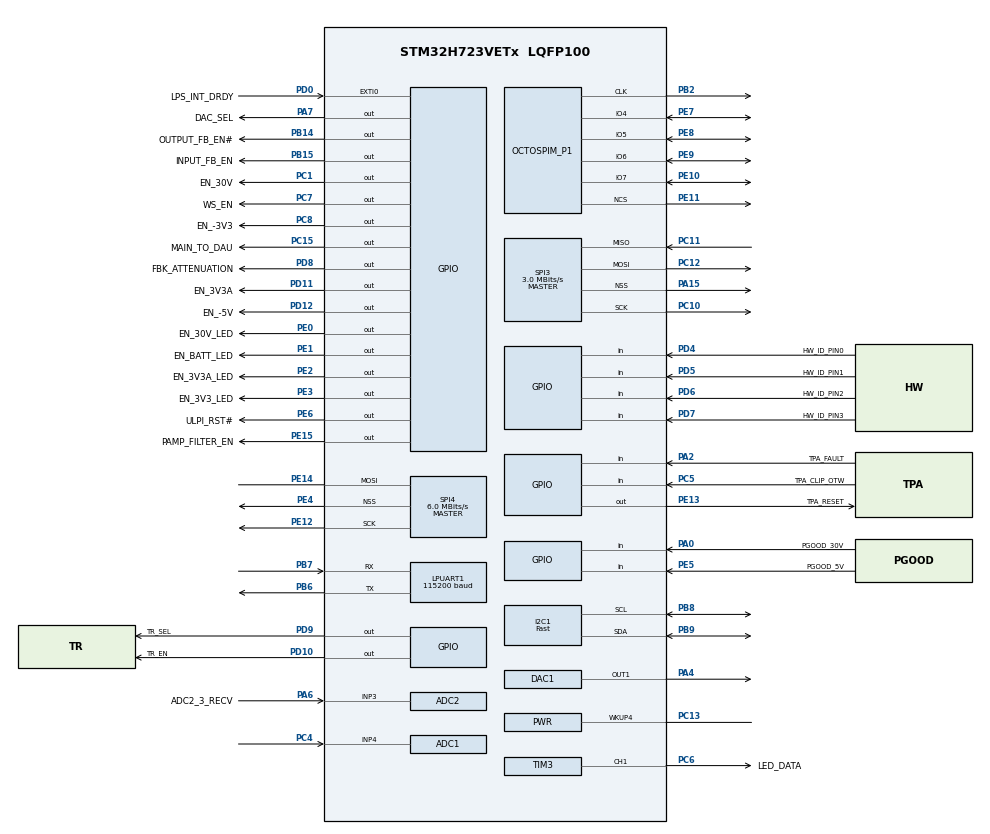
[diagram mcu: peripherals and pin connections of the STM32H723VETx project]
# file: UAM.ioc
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ADC1.Channel-1\#ChannelRegularConversion=ADC_CHANNEL_4
ADC1.ConversionDataManagement=ADC_CONVERSIONDATA_DMA_CIRCULAR
ADC1.ExternalTrigConv=ADC_EXTERNALTRIG_T6_TRGO
ADC1.NbrOfConversionFlag=1
ADC1.OffsetNumber-1\#ChannelRegularConversion=ADC_OFFSET_NONE
ADC1.OffsetSignedSaturation-1\#ChannelRegularConversion=DISABLE
ADC1.Rank-1\#ChannelRegularConversion=1
ADC1.SamplingTime-1\#ChannelRegularConversion=ADC_SAMPLETIME_2CYCLES_5
ADC1.master=1
ADC2.Channel-0\#ChannelRegularConversion=ADC_CHANNEL_3
ADC2.ConversionDataManagement=ADC_CONVERSIONDATA_DMA_CIRCULAR
ADC2.ExternalTrigConv=ADC_EXTERNALTRIG_T8_TRGO
ADC2.NbrOfConversion=1
ADC2.NbrOfConversionFlag=1
ADC2.OffsetNumber-0\#ChannelRegularConversion=ADC_OFFSET_NONE
ADC2.OffsetSignedSaturation-0\#ChannelRegularConversion=DISABLE
ADC2.OversamplingMode=DISABLE
ADC2.Rank-0\#ChannelRegularConversion=1
ADC2.Ratio=1
ADC2.Resolution=ADC_RESOLUTION_16B
ADC2.SamplingTime-0\#ChannelRegularConversion=ADC_SAMPLETIME_2CYCLES_5
ADC3.Channel-0\#ChannelRegularConversion=ADC_CHANNEL_TEMPSENSOR
ADC3.ContinuousConvMode=DISABLE
ADC3.ConversionDataManagement=ADC_CONVERSIONDATA_DR
ADC3.DMAContinuousRequests=DISABLE
ADC3.ExternalTrigConv=ADC_SOFTWARE_START
ADC3.NbrOfConversion=1
ADC3.NbrOfConversionFlag=1
ADC3.OffsetNumber-0\#ChannelRegularConversion=ADC_OFFSET_NONE
ADC3.OffsetSign-0\#ChannelRegularConversion=ADC3_OFFSET_SIGN_NEGATIVE
ADC3.Overrun=ADC_OVR_DATA_PRESERVED
ADC3.OversamplingMode=ENABLE
ADC3.Rank-0\#ChannelRegularConversion=1
ADC3.Ratio=ADC3_OVERSAMPLING_RATIO_16
ADC3.RightBitShift=ADC_RIGHTBITSHIFT_4
ADC3.SamplingTime-0\#ChannelRegularConversion=ADC3_SAMPLETIME_640CYCLES_5
Bdma.LPUART1_RX.0.Direction=DMA_PERIPH_TO_MEMORY
Bdma.LPUART1_RX.0.EventEnable=DISABLE
Bdma.LPUART1_RX.0.Instance=BDMA_Channel0
Bdma.LPUART1_RX.0.MemDataAlignment=DMA_MDATAALIGN_BYTE
Bdma.LPUART1_RX.0.MemInc=DMA_MINC_ENABLE
Bdma.LPUART1_RX.0.Mode=DMA_NORMAL
Bdma.LPUART1_RX.0.PeriphDataAlignment=DMA_PDATAALIGN_BYTE
Bdma.LPUART1_RX.0.PeriphInc=DMA_PINC_DISABLE
Bdma.LPUART1_RX.0.Polarity=HAL_DMAMUX_REQ_GEN_RISING
Bdma.LPUART1_RX.0.Priority=DMA_PRIORITY_MEDIUM
Bdma.LPUART1_RX.0.RequestNumber=1
Bdma.LPUART1_RX.0.SignalID=NONE
Bdma.LPUART1_RX.0.SyncEnable=DISABLE
Bdma.LPUART1_RX.0.SyncPolarity=HAL_DMAMUX_SYNC_NO_EVENT
Bdma.LPUART1_RX.0.SyncRequestNumber=1
Bdma.LPUART1_RX.0.SyncSignalID=NONE
Bdma.LPUART1_TX.1.Direction=DMA_MEMORY_TO_PERIPH
Bdma.LPUART1_TX.1.EventEnable=DISABLE
Bdma.LPUART1_TX.1.Instance=BDMA_Channel1
Bdma.LPUART1_TX.1.MemDataAlignment=DMA_MDATAALIGN_BYTE
Bdma.LPUART1_TX.1.MemInc=DMA_MINC_ENABLE
Bdma.LPUART1_TX.1.Mode=DMA_NORMAL
Bdma.LPUART1_TX.1.PeriphDataAlignment=DMA_PDATAALIGN_BYTE
Bdma.LPUART1_TX.1.PeriphInc=DMA_PINC_DISABLE
Bdma.LPUART1_TX.1.Polarity=HAL_DMAMUX_REQ_GEN_RISING
Bdma.LPUART1_TX.1.Priority=DMA_PRIORITY_MEDIUM
Bdma.LPUART1_TX.1.RequestNumber=1
Bdma.LPUART1_TX.1.SignalID=NONE
Bdma.LPUART1_TX.1.SyncEnable=DISABLE
Bdma.LPUART1_TX.1.SyncPolarity=HAL_DMAMUX_SYNC_NO_EVENT
Bdma.LPUART1_TX.1.SyncRequestNumber=1
Bdma.LPUART1_TX.1.SyncSignalID=NONE
Bdma.Request0=LPUART1_RX
Bdma.Request1=LPUART1_TX
Bdma.RequestsNb=2
CORTEX_M7.AccessPermission_S-Cortex_Memory_Protection_Unit_Region1_Settings_S=MPU_REGION_FULL_ACCESS
CORTEX_M7.AccessPermission_S-Cortex_Memory_Protection_Unit_Region2_Settings_S=MPU_REGION_FULL_ACCESS
CORTEX_M7.AccessPermission_Spec=MPU_REGION_NO_ACCESS
CORTEX_M7.BaseAddress_S-Cortex_Memory_Protection_Unit_Region1_Settings_S=0x30000000
CORTEX_M7.BaseAddress_S-Cortex_Memory_Protection_Unit_Region2_Settings_S=0x38800000
CORTEX_M7.CPU_DCache=Enabled
CORTEX_M7.CPU_ICache=Enabled
CORTEX_M7.DisableExec_S-Cortex_Memory_Protection_Unit_Region1_Settings_S=MPU_INSTRUCTION_ACCESS_DISABLE
CORTEX_M7.DisableExec_S-Cortex_Memory_Protection_Unit_Region2_Settings_S=MPU_INSTRUCTION_ACCESS_DISABLE
CORTEX_M7.DisableExec_Spec=MPU_INSTRUCTION_ACCESS_DISABLE
CORTEX_M7.Enable_S-Cortex_Memory_Protection_Unit_Region1_Settings_S=MPU_REGION_ENABLE
CORTEX_M7.Enable_S-Cortex_Memory_Protection_Unit_Region2_Settings_S=MPU_REGION_ENABLE
CORTEX_M7.IsBufferable_Spec=MPU_ACCESS_NOT_BUFFERABLE
CORTEX_M7.IsCacheable_Spec=MPU_ACCESS_NOT_CACHEABLE
CORTEX_M7.IsShareable_S-Cortex_Memory_Protection_Unit_Region1_Settings_S=MPU_ACCESS_NOT_SHAREABLE
CORTEX_M7.IsShareable_Spec=MPU_ACCESS_NOT_SHAREABLE
CORTEX_M7.Size_S-Cortex_Memory_Protection_Unit_Region1_Settings_S=MPU_REGION_SIZE_32KB
CORTEX_M7.Size_S-Cortex_Memory_Protection_Unit_Region2_Settings_S=MPU_REGION_SIZE_4KB
CORTEX_M7.Size_Spec=MPU_REGION_SIZE_4GB
CORTEX_M7.TypeExtField_S-Cortex_Memory_Protection_Unit_Region1_Settings_S=MPU_TEX_LEVEL0
CORTEX_M7.default_mode_Activation=1
DAC1.DAC_Channel-DAC_OUT1=DAC_CHANNEL_1
DAC1.DAC_Trigger-DAC_OUT1=DAC_TRIGGER_T6_TRGO
Dma.ADC1.2.Direction=DMA_PERIPH_TO_MEMORY
Dma.ADC1.2.EventEnable=DISABLE
Dma.ADC1.2.FIFOMode=DMA_FIFOMODE_DISABLE
Dma.ADC1.2.Instance=DMA2_Stream0
Dma.ADC1.2.MemDataAlignment=DMA_MDATAALIGN_HALFWORD
Dma.ADC1.2.MemInc=DMA_MINC_ENABLE
Dma.ADC1.2.Mode=DMA_CIRCULAR
Dma.ADC1.2.PeriphDataAlignment=DMA_PDATAALIGN_HALFWORD
Dma.ADC1.2.PeriphInc=DMA_PINC_DISABLE
Dma.ADC1.2.Polarity=HAL_DMAMUX_REQ_GEN_RISING
Dma.ADC1.2.Priority=DMA_PRIORITY_VERY_HIGH
Dma.ADC1.2.RequestNumber=1
Dma.ADC1.2.SignalID=NONE
Dma.ADC1.2.SyncEnable=DISABLE
Dma.ADC1.2.SyncPolarity=HAL_DMAMUX_SYNC_NO_EVENT
Dma.ADC1.2.SyncRequestNumber=1
Dma.ADC1.2.SyncSignalID=NONE
Dma.ADC2.1.Direction=DMA_PERIPH_TO_MEMORY
Dma.ADC2.1.EventEnable=DISABLE
Dma.ADC2.1.FIFOMode=DMA_FIFOMODE_DISABLE
Dma.ADC2.1.Instance=DMA2_Stream2
Dma.ADC2.1.MemDataAlignment=DMA_MDATAALIGN_HALFWORD
Dma.ADC2.1.MemInc=DMA_MINC_ENABLE
Dma.ADC2.1.Mode=DMA_CIRCULAR
Dma.ADC2.1.PeriphDataAlignment=DMA_PDATAALIGN_HALFWORD
Dma.ADC2.1.PeriphInc=DMA_PINC_DISABLE
Dma.ADC2.1.Polarity=HAL_DMAMUX_REQ_GEN_RISING
Dma.ADC2.1.Priority=DMA_PRIORITY_VERY_HIGH
Dma.ADC2.1.RequestNumber=1
Dma.ADC2.1.SignalID=NONE
Dma.ADC2.1.SyncEnable=DISABLE
Dma.ADC2.1.SyncPolarity=HAL_DMAMUX_SYNC_NO_EVENT
Dma.ADC2.1.SyncRequestNumber=1
Dma.ADC2.1.SyncSignalID=NONE
Dma.DAC1_CH1.3.Direction=DMA_MEMORY_TO_PERIPH
Dma.DAC1_CH1.3.EventEnable=DISABLE
Dma.DAC1_CH1.3.FIFOMode=DMA_FIFOMODE_DISABLE
Dma.DAC1_CH1.3.Instance=DMA1_Stream1
Dma.DAC1_CH1.3.MemDataAlignment=DMA_MDATAALIGN_HALFWORD
Dma.DAC1_CH1.3.MemInc=DMA_MINC_ENABLE
Dma.DAC1_CH1.3.Mode=DMA_CIRCULAR
Dma.DAC1_CH1.3.PeriphDataAlignment=DMA_PDATAALIGN_HALFWORD
Dma.DAC1_CH1.3.PeriphInc=DMA_PINC_DISABLE
Dma.DAC1_CH1.3.Polarity=HAL_DMAMUX_REQ_GEN_RISING
Dma.DAC1_CH1.3.Priority=DMA_PRIORITY_VERY_HIGH
Dma.DAC1_CH1.3.RequestNumber=1
Dma.DAC1_CH1.3.SignalID=NONE
Dma.DAC1_CH1.3.SyncEnable=DISABLE
Dma.DAC1_CH1.3.SyncPolarity=HAL_DMAMUX_SYNC_NO_EVENT
Dma.DAC1_CH1.3.SyncRequestNumber=1
Dma.DAC1_CH1.3.SyncSignalID=NONE
Dma.Request0=TIM3_CH1
Dma.Request1=ADC2
Dma.Request2=ADC1
Dma.Request3=DAC1_CH1
Dma.Request4=SPI4_RX
Dma.Request5=SPI4_TX
Dma.SPI4_RX.4.Direction=DMA_PERIPH_TO_MEMORY
Dma.SPI4_RX.4.EventEnable=DISABLE
Dma.SPI4_RX.4.FIFOMode=DMA_FIFOMODE_DISABLE
Dma.SPI4_RX.4.Instance=DMA1_Stream4
Dma.SPI4_RX.4.MemDataAlignment=DMA_MDATAALIGN_HALFWORD
Dma.SPI4_RX.4.MemInc=DMA_MINC_ENABLE
Dma.SPI4_RX.4.Mode=DMA_NORMAL
Dma.SPI4_RX.4.PeriphDataAlignment=DMA_PDATAALIGN_HALFWORD
Dma.SPI4_RX.4.PeriphInc=DMA_PINC_DISABLE
Dma.SPI4_RX.4.Polarity=HAL_DMAMUX_REQ_GEN_RISING
Dma.SPI4_RX.4.Priority=DMA_PRIORITY_MEDIUM
Dma.SPI4_RX.4.RequestNumber=1
Dma.SPI4_RX.4.SignalID=NONE
Dma.SPI4_RX.4.SyncEnable=DISABLE
Dma.SPI4_RX.4.SyncPolarity=HAL_DMAMUX_SYNC_NO_EVENT
Dma.SPI4_RX.4.SyncRequestNumber=1
Dma.SPI4_RX.4.SyncSignalID=NONE
Dma.SPI4_TX.5.Direction=DMA_MEMORY_TO_PERIPH
Dma.SPI4_TX.5.EventEnable=DISABLE
Dma.SPI4_TX.5.FIFOMode=DMA_FIFOMODE_DISABLE
Dma.SPI4_TX.5.Instance=DMA1_Stream3
Dma.SPI4_TX.5.MemDataAlignment=DMA_MDATAALIGN_HALFWORD
Dma.SPI4_TX.5.MemInc=DMA_MINC_ENABLE
Dma.SPI4_TX.5.Mode=DMA_NORMAL
Dma.SPI4_TX.5.PeriphDataAlignment=DMA_PDATAALIGN_HALFWORD
Dma.SPI4_TX.5.PeriphInc=DMA_PINC_DISABLE
Dma.SPI4_TX.5.Polarity=HAL_DMAMUX_REQ_GEN_RISING
Dma.SPI4_TX.5.Priority=DMA_PRIORITY_MEDIUM
Dma.SPI4_TX.5.RequestNumber=1
Dma.SPI4_TX.5.SignalID=NONE
Dma.SPI4_TX.5.SyncEnable=DISABLE
Dma.SPI4_TX.5.SyncPolarity=HAL_DMAMUX_SYNC_NO_EVENT
Dma.SPI4_TX.5.SyncRequestNumber=1
Dma.SPI4_TX.5.SyncSignalID=NONE
Dma.TIM3_CH1.0.Direction=DMA_MEMORY_TO_PERIPH
Dma.TIM3_CH1.0.EventEnable=DISABLE
Dma.TIM3_CH1.0.FIFOMode=DMA_FIFOMODE_DISABLE
Dma.TIM3_CH1.0.Instance=DMA1_Stream0
Dma.TIM3_CH1.0.MemDataAlignment=DMA_MDATAALIGN_HALFWORD
Dma.TIM3_CH1.0.MemInc=DMA_MINC_ENABLE
Dma.TIM3_CH1.0.Mode=DMA_NORMAL
Dma.TIM3_CH1.0.PeriphDataAlignment=DMA_PDATAALIGN_HALFWORD
Dma.TIM3_CH1.0.PeriphInc=DMA_PINC_DISABLE
Dma.TIM3_CH1.0.Polarity=HAL_DMAMUX_REQ_GEN_RISING
Dma.TIM3_CH1.0.Priority=DMA_PRIORITY_HIGH
Dma.TIM3_CH1.0.RequestNumber=1
Dma.TIM3_CH1.0.SignalID=NONE
Dma.TIM3_CH1.0.SyncEnable=DISABLE
Dma.TIM3_CH1.0.SyncPolarity=HAL_DMAMUX_SYNC_NO_EVENT
Dma.TIM3_CH1.0.SyncRequestNumber=1
Dma.TIM3_CH1.0.SyncSignalID=NONE
FREERTOS.HEAP_NUMBER=4
FREERTOS.Mutexes01=dau_uart_mutex,Dynamic,NULL,Available
FREERTOS.Tasks01=tusb_task,47,2048,startTusbTask,Default,NULL,Static,tusb_task_buffer,tusb_task_control_block;message_task,44,8192,startMessTask,Default,NULL,Static,mess_task_buffer,mess_task_control_block;sys_task,31,256,startSystemManagementTask,Default,NULL,Static,sys_task_buffer,sys_task_control_block;comm_task,30,2048,startCommunicationTask,Default,NULL,Static,comm_task_buffer,comm_task_control_block;cfg_task,16,512,startconfigTask,Default,NULL,Static,cfg_task_buffer,cfg_task_control_block;dac_task,46,1024,startDacTask,Default,NULL,Static,dac_task_buffer,dac_task_control_block;mac_task,25,2048,startMacTask,Default,NULL,Static,mac_task_buffer,mac_task_control_block;filt_task,45,512,startFiltTask,Default,NULL,Static,filt_task_buffer,filt_task_control_block;hil_task,46,1024,startHilTask,Default,NULL,Static,hil_task_buffer,hil_task_control_block
FREERTOS.configCHECK_FOR_STACK_OVERFLOW=2
FREERTOS.configENABLE_FPU=1
FREERTOS.configGENERATE_RUN_TIME_STATS=1
FREERTOS.configRECORD_STACK_HIGH_ADDRESS=0
FREERTOS.configTOTAL_HEAP_SIZE=48000
FREERTOS.configUSE_NEWLIB_REENTRANT=1
FREERTOS.configUSE_TICKLESS_IDLE=1
I2C1.I2C_Speed_Mode=I2C_Fast
I2C1.Timing=0x00B03FDB
LPUART1.BaudRate=115200
Mcu.Family=STM32H7
Mcu.Name=STM32H723VETx
Mcu.Package=LQFP100
NVIC.ADC3_IRQn=true\:5\:0\:false\:false\:true\:true\:true\:true\:true
NVIC.BDMA_Channel0_IRQn=true\:5\:0\:false\:false\:true\:true\:false\:true\:true
NVIC.BDMA_Channel1_IRQn=true\:5\:0\:false\:false\:true\:true\:false\:true\:true
NVIC.DMA1_Stream0_IRQn=true\:5\:0\:false\:false\:true\:true\:false\:true\:true
NVIC.DMA1_Stream1_IRQn=true\:5\:0\:false\:false\:true\:true\:false\:true\:true
NVIC.DMA1_Stream3_IRQn=true\:5\:0\:false\:false\:true\:false\:false\:true\:true
NVIC.DMA1_Stream4_IRQn=true\:5\:0\:false\:false\:true\:true\:false\:true\:true
NVIC.DMA2_Stream0_IRQn=true\:5\:0\:false\:false\:true\:false\:false\:true\:true
NVIC.DMA2_Stream2_IRQn=true\:5\:0\:false\:false\:true\:true\:false\:true\:true
NVIC.EXTI0_IRQn=true\:5\:0\:false\:false\:true\:true\:true\:true\:true
NVIC.FMAC_IRQn=true\:5\:0\:false\:false\:true\:true\:true\:true\:true
NVIC.I2C1_EV_IRQn=true\:5\:0\:false\:false\:true\:true\:true\:true\:true
NVIC.LPUART1_IRQn=true\:5\:0\:false\:false\:true\:true\:true\:true\:true
NVIC.PriorityGroup=NVIC_PRIORITYGROUP_4
NVIC.SPI3_IRQn=true\:5\:0\:false\:false\:true\:true\:true\:true\:true
NVIC.SPI4_IRQn=true\:5\:0\:false\:false\:true\:true\:true\:true\:true
NVIC.TIM16_IRQn=true\:5\:0\:false\:false\:true\:true\:true\:true\:true
NVIC.TIM17_IRQn=true\:5\:0\:false\:false\:true\:true\:true\:true\:true
NVIC.TIM2_IRQn=true\:15\:0\:false\:false\:true\:false\:false\:true\:true
NVIC.TIM3_IRQn=true\:5\:0\:false\:false\:true\:true\:true\:true\:true
NVIC.TIM6_DAC_IRQn=true\:5\:0\:false\:false\:true\:true\:true\:true\:true
NVIC.TimeBase=TIM2_IRQn
NVIC.TimeBaseIP=TIM2
OCTOSPI1.ClockPrescaler=2
PA0.GPIO_Label=PGOOD_30V
PA0.Signal=GPIO_Input
PA13(JTMS/SWDIO).Mode=Trace_Asynchronous_SW
PA13(JTMS/SWDIO).Signal=DEBUG_JTMS-SWDIO
PA14(JTCK/SWCLK).Mode=Trace_Asynchronous_SW
PA14(JTCK/SWCLK).Signal=DEBUG_JTCK-SWCLK
PA15(JTDI).Mode=NSS_Signal_Hard_Output
PA15(JTDI).Signal=SPI3_NSS
PA2.GPIO_Label=TPA_FAULT
PA2.Signal=GPIO_Input
PA4.Signal=COMP_DAC11_group
PA6.GPIO_Label=ADC2_3_RECV
PA6.Signal=ADCx_INP3
PA7.GPIO_Label=DAC_SEL
PA7.Signal=GPIO_Output
PB14.GPIO_Label=OUTPUT_FB_EN\#
PB14.Signal=GPIO_Output
PB15.GPIO_Label=INPUT_FB_EN
PB15.Signal=GPIO_Output
PB2.Mode=O1_P1_CLK
PB2.Signal=OCTOSPIM_P1_CLK
PB3(JTDO/TRACESWO).Mode=Trace_Asynchronous_SW
PB3(JTDO/TRACESWO).Signal=DEBUG_JTDO-SWO
PB6.Mode=Asynchronous
PB6.Signal=LPUART1_TX
PB7.Mode=Asynchronous
PB7.Signal=LPUART1_RX
PB8.Mode=I2C
PB8.Signal=I2C1_SCL
PB9.Mode=I2C
PB9.Signal=I2C1_SDA
PC1.GPIO_Label=EN_30V
PC1.Signal=GPIO_Output
PC10.Mode=Full_Duplex_Master
PC10.Signal=SPI3_SCK
PC11.Mode=Full_Duplex_Master
PC11.Signal=SPI3_MISO
PC12.Mode=Full_Duplex_Master
PC12.Signal=SPI3_MOSI
PC13.Mode=WakeUp4
PC13.Signal=PWR_WKUP4
PC14-OSC32_IN.Mode=LSE-External-Clock-Source
PC14-OSC32_IN.Signal=RCC_OSC32_IN
PC15-OSC32_OUT.GPIO_Label=MAIN_TO_DAU
PC15-OSC32_OUT.Signal=GPIO_Output
PC4.Signal=ADCx_INP4
PC5.GPIO_Label=TPA_CLIP_OTW
PC5.Signal=GPIO_Input
PC6.GPIO_Label=LED_DATA
PC6.Signal=S_TIM3_CH1
PC7.GPIO_Label=WS_EN
PC7.Signal=GPIO_Output
PC8.GPIO_Label=EN_-3V3
PC8.Signal=GPIO_Output
PD0.GPIO_Label=LPS_INT_DRDY
PD0.GPIO_PuPd=GPIO_PULLDOWN
PD0.Signal=GPXTI0
PD10.GPIO_Label=TR_EN
PD10.Signal=GPIO_Output
PD11.GPIO_Label=EN_3V3A
PD11.Signal=GPIO_Output
PD12.GPIO_Label=EN_-5V
PD12.Signal=GPIO_Output
PD4.GPIO_Label=HW_ID_PIN0
PD4.Signal=GPIO_Input
PD5.GPIO_Label=HW_ID_PIN1
PD5.Signal=GPIO_Input
PD6.GPIO_Label=HW_ID_PIN2
PD6.Signal=GPIO_Input
PD7.GPIO_Label=HW_ID_PIN3
PD7.Signal=GPIO_Input
PD8.GPIO_Label=FBK_ATTENUATION
PD8.PinState=GPIO_PIN_SET
PD8.Signal=GPIO_Output
PD9.GPIO_Label=TR_SEL
PD9.Signal=GPIO_Output
PE0.GPIO_Label=EN_30V_LED
PE0.Signal=GPIO_Output
PE1.GPIO_Label=EN_BATT_LED
PE1.Signal=GPIO_Output
PE10.Mode=OCTOSPI1_IOL_Port1H
PE10.Signal=OCTOSPIM_P1_IO7
PE11.Mode=OCTOSPI1_Port1_NCS
PE11.Signal=OCTOSPIM_P1_NCS
PE12.Mode=Simplex_Bidirectional_Master
PE12.Signal=SPI4_SCK
PE13.GPIO_Label=TPA_RESET
PE13.Signal=GPIO_Output
PE14.Mode=Simplex_Bidirectional_Master
PE14.Signal=SPI4_MOSI
PE15.GPIO_Label=PAMP_FILTER_EN
PE15.Signal=GPIO_Output
PE2.GPIO_Label=EN_3V3A_LED
PE2.Signal=GPIO_Output
PE3.GPIO_Label=EN_3V3_LED
PE3.Signal=GPIO_Output
PE4.Mode=NSS_Signal_Hard_Output
PE4.Signal=SPI4_NSS
PE5.GPIO_Label=PGOOD_5V
PE5.Signal=GPIO_Input
PE6.GPIO_Label=ULPI_RST\#
PE6.Signal=GPIO_Output
PE7.Mode=OCTOSPI1_IOL_Port1H
PE7.Signal=OCTOSPIM_P1_IO4
PE8.Mode=OCTOSPI1_IOL_Port1H
PE8.Signal=OCTOSPIM_P1_IO5
PE9.Mode=OCTOSPI1_IOL_Port1H
PE9.Signal=OCTOSPIM_P1_IO6
PH0-OSC_IN.Mode=HSE-External-Oscillator
PH0-OSC_IN.Signal=RCC_OSC_IN
PH1-OSC_OUT.Mode=HSE-External-Oscillator
PH1-OSC_OUT.Signal=RCC_OSC_OUT
ProjectManager.HeapSize=0x200
ProjectManager.StackSize=0x400
ProjectManager.TargetToolchain=STM32CubeIDE
RCC.ADCFreq_Value=48000000
RCC.APB1Freq_Value=120000000
RCC.APB2Freq_Value=120000000
RCC.APB3Freq_Value=120000000
RCC.APB4Freq_Value=120000000
RCC.CortexFreq_Value=480000000
RCC.D1PPRE=RCC_APB3_DIV2
RCC.D2PPRE1=RCC_APB1_DIV2
RCC.D2PPRE2=RCC_APB2_DIV2
RCC.D3PPRE=RCC_APB4_DIV2
RCC.DIVM1=1
RCC.DIVM2=1
RCC.DIVM3=4
RCC.DIVN1=60
RCC.DIVN2=24
RCC.DIVN3=120
RCC.DIVP1=1
RCC.DIVP2=4
RCC.DIVQ1=10
RCC.DIVQ3=5
RCC.HCLKFreq_Value=240000000
RCC.HPRE=RCC_HCLK_DIV2
RCC.HSE_VALUE=8000000
RCC.PLL1_VCO_SEL-AdvancedSettings=RCC_PLL1VCOMEDIUM
RCC.PLL2FRACN=0
RCC.PLL2_VCI_Range-AdvancedSettings=RCC_PLL2VCIRANGE_0
RCC.PLL3FRACN=0
RCC.PLLFRACN=0
RCC.PLLSourceVirtual=RCC_PLLSOURCE_HSE
RCC.PWR_Regulator_Voltage_Scale=PWR_REGULATOR_VOLTAGE_SCALE0
RCC.RTCClockSelection=RCC_RTCCLKSOURCE_LSE
RCC.SYSCLKFreq_VALUE=480000000
RCC.SYSCLKSource=RCC_SYSCLKSOURCE_PLLCLK
RCC.Spi45ClockSelection=RCC_SPI45CLKSOURCE_PLL2
RCC.USBCLockSelection=RCC_USBCLKSOURCE_PLL3
RCC.USBFreq_Value=48000000
SH.ADCx_INP3.0=ADC2_INP3,IN3-Single-Ended
SH.ADCx_INP4.0=ADC1_INP4,IN4-Single-Ended
SH.COMP_DAC11_group.0=DAC1_OUT1,DAC_OUT1
SH.S_TIM3_CH1.0=TIM3_CH1,PWM Generation1 CH1
SPI3.BaudRatePrescaler=SPI_BAUDRATEPRESCALER_16
SPI3.CalculateBaudRate=3.0 MBits/s
SPI3.DataSize=SPI_DATASIZE_8BIT
SPI3.Direction=SPI_DIRECTION_2LINES
SPI3.Mode=SPI_MODE_MASTER
SPI3.VirtualNSS=VM_NSSHARD
SPI3.VirtualType=VM_MASTER
SPI4.BaudRatePrescaler=SPI_BAUDRATEPRESCALER_16
SPI4.CalculateBaudRate=6.0 MBits/s
SPI4.DataSize=SPI_DATASIZE_16BIT
SPI4.Direction=SPI_DIRECTION_1LINE
SPI4.Mode=SPI_MODE_MASTER
SPI4.VirtualNSS=VM_NSSHARD
SPI4.VirtualType=VM_MASTER
TIM16.Period=1000-1
TIM16.Prescaler=240-1
TIM17.Period=100-1
TIM17.Prescaler=240-1
TIM3.Channel-PWM\ Generation1\ CH1=TIM_CHANNEL_1
TIM3.OCFastMode_PWM-PWM\ Generation1\ CH1=TIM_OCFAST_DISABLE
TIM3.OCPolarity_1=TIM_OCPOLARITY_LOW
TIM3.Period=100-1
TIM3.Prescaler=3-1
TIM3.Pulse-PWM\ Generation1\ CH1=0
TIM6.Period=4-1
TIM6.Prescaler=120-1
TIM6.TIM_MasterOutputTrigger=TIM_TRGO_UPDATE
TIM8.AutoReloadPreload=TIM_AUTORELOAD_PRELOAD_ENABLE
TIM8.CounterMode=TIM_COUNTERMODE_UP
TIM8.Period=2-1
TIM8.Prescaler=1000-1
TIM8.TIM_MasterOutputTrigger=TIM_TRGO_UPDATE
VP_ADC3_TempSens_Input.Mode=IN-TempSens
VP_CORDIC_VS_CORDIC.Mode=CORDIC_Activate
VP_DTS_VS-DTS.Mode=DTS
VP_FMAC_VS_FMAC.Mode=FMAC_Activate
VP_FREERTOS_VS_CMSIS_V2.Mode=CMSIS_V2
VP_MEMORYMAP_VS_MEMORYMAP.Mode=CurAppReg
VP_OCTOSPI1_VS_quad.Mode=quad_mode
VP_RTC_VS_RTC_Activate.Mode=RTC_Enabled
VP_SYS_VS_tim2.Mode=TIM2
VP_TIM16_VS_ClockSourceINT.Mode=Enable_Timer
VP_TIM17_VS_ClockSourceINT.Mode=Enable_Timer
VP_TIM3_VS_ClockSourceINT.Mode=Internal
VP_TIM6_VS_ClockSourceINT.Mode=Enable_Timer
VP_TIM8_VS_ClockSourceINT.Mode=Internal
VP_VREFBUF_V_VREFBUF.Mode=ExternalMode
board=custom

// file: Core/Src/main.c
/* USER CODE BEGIN Header */
/**
  ******************************************************************************
  * @file           : main.c
  * @brief          : Main program body
  ******************************************************************************
  * @attention
  *
  * Copyright (c) 2025 STMicroelectronics.
  * All rights reserved.
  *
  * This software is licensed under terms that can be found in the LICENSE file
  * in the root directory of this software component.
  * If no LICENSE file comes with this software, it is provided AS-IS.
  *
  ******************************************************************************
  */

  /**
  * Modifications Copyright (c) 2025 OpenAquatix Contributors
  * Licensed under MIT License (see LICENSE file)
  *
  * Modified by: Addition of OpenAquatix application
  */

/* USER CODE END Header */
#include "main.h"
#include "FreeRTOS.h"
#include "cmsis_os2.h"

/* USER CODE BEGIN Includes */
#include "ws2812b-driver.h"
#include "pga113-driver.h"
#include "power_leds.h"
#include "hmi_usb.h"
#include "comm_main.h"
#include "mess_main.h"
#include "cfg_main.h"
#include "sys_main.h"
#include "dac_main.h"
#include "mac_main.h"
#include "filt_main.h"
#include "cfg_parameters.h"
#include "stm32h7xx_ll_cordic.h"
#include "pwr_domains.h"
#include "core_cm7.h"
#include "tusb.h"
#include "usb_main.h"
#include "hil_main.h"
/* USER CODE END Includes */

typedef StaticTask_t osStaticThreadDef_t;

ADC_HandleTypeDef hadc1;
ADC_HandleTypeDef hadc2;
ADC_HandleTypeDef hadc3;
DMA_HandleTypeDef hdma_adc1;
DMA_HandleTypeDef hdma_adc2;

CORDIC_HandleTypeDef hcordic;

DAC_HandleTypeDef hdac1;
DMA_HandleTypeDef hdma_dac1_ch1;

DTS_HandleTypeDef hdts;

FMAC_HandleTypeDef hfmac;

I2C_HandleTypeDef hi2c1;

UART_HandleTypeDef hlpuart1;
DMA_HandleTypeDef hdma_lpuart1_rx;
DMA_HandleTypeDef hdma_lpuart1_tx;

OSPI_HandleTypeDef hospi1;

RTC_HandleTypeDef hrtc;

SPI_HandleTypeDef hspi3;
SPI_HandleTypeDef hspi4;
DMA_HandleTypeDef hdma_spi4_rx;
DMA_HandleTypeDef hdma_spi4_tx;

TIM_HandleTypeDef htim3;
TIM_HandleTypeDef htim6;
TIM_HandleTypeDef htim8;
TIM_HandleTypeDef htim16;
TIM_HandleTypeDef htim17;
DMA_HandleTypeDef hdma_tim3_ch1;

/* Definitions for tusb_task */
osThreadId_t tusb_taskHandle;
uint32_t tusb_task_buffer[ 2048 ];
osStaticThreadDef_t tusb_task_control_block;
const osThreadAttr_t tusb_task_attributes = {
  .name = "USB",
  .cb_mem = &tusb_task_control_block,
  .cb_size = sizeof(tusb_task_control_block),
  .stack_mem = &tusb_task_buffer[0],
  .stack_size = sizeof(tusb_task_buffer),
  .priority = (osPriority_t) osPriorityHigh7,
};
/* Definitions for message_task */
osThreadId_t message_taskHandle;
uint32_t mess_task_buffer[ 8192 ] __attribute__((section(".dtcm")));
osStaticThreadDef_t mess_task_control_block;
const osThreadAttr_t message_task_attributes = {
  .name = MESS_TASK_NAME,
  .cb_mem = &mess_task_control_block,
  .cb_size = sizeof(mess_task_control_block),
  .stack_mem = &mess_task_buffer[0],
  .stack_size = sizeof(mess_task_buffer),
  .priority = (osPriority_t) osPriorityHigh4,
};
/* Definitions for sys_task */
osThreadId_t sys_taskHandle;
uint32_t sys_task_buffer[ 256 ];
osStaticThreadDef_t sys_task_control_block;
const osThreadAttr_t sys_task_attributes = {
  .name = "SYS",
  .cb_mem = &sys_task_control_block,
  .cb_size = sizeof(sys_task_control_block),
  .stack_mem = &sys_task_buffer[0],
  .stack_size = sizeof(sys_task_buffer),
  .priority = (osPriority_t) osPriorityNormal7,
};
/* Definitions for comm_task */
osThreadId_t comm_taskHandle;
uint32_t comm_task_buffer[ 2048 ];
osStaticThreadDef_t comm_task_control_block;
const osThreadAttr_t comm_task_attributes = {
  .name = "COMM",
  .cb_mem = &comm_task_control_block,
  .cb_size = sizeof(comm_task_control_block),
  .stack_mem = &comm_task_buffer[0],
  .stack_size = sizeof(comm_task_buffer),
  .priority = (osPriority_t) osPriorityNormal6,
};
/* Definitions for cfg_task */
osThreadId_t cfg_taskHandle;
uint32_t cfg_task_buffer[ 512 ];
osStaticThreadDef_t cfg_task_control_block;
const osThreadAttr_t cfg_task_attributes = {
  .name = "CFG",
  .cb_mem = &cfg_task_control_block,
  .cb_size = sizeof(cfg_task_control_block),
  .stack_mem = &cfg_task_buffer[0],
  .stack_size = sizeof(cfg_task_buffer),
  .priority = (osPriority_t) osPriorityBelowNormal,
};
/* Definitions for dac_task */
osThreadId_t dac_taskHandle;
uint32_t dac_task_buffer[ 1024 ];
osStaticThreadDef_t dac_task_control_block;
const osThreadAttr_t dac_task_attributes = {
  .name = "DAC",
  .cb_mem = &dac_task_control_block,
  .cb_size = sizeof(dac_task_control_block),
  .stack_mem = &dac_task_buffer[0],
  .stack_size = sizeof(dac_task_buffer),
  .priority = (osPriority_t) osPriorityHigh6,
};
/* Definitions for mac_task */
osThreadId_t mac_taskHandle;
uint32_t mac_task_buffer[ 2048 ];
osStaticThreadDef_t mac_task_control_block;
const osThreadAttr_t mac_task_attributes = {
  .name = "MAC",
  .cb_mem = &mac_task_control_block,
  .cb_size = sizeof(mac_task_control_block),
  .stack_mem = &mac_task_buffer[0],
  .stack_size = sizeof(mac_task_buffer),
  .priority = (osPriority_t) osPriorityNormal1,
};
/* Definitions for filt_task */
osThreadId_t filt_taskHandle;
uint32_t filt_task_buffer[ 512 ];
osStaticThreadDef_t filt_task_control_block;
const osThreadAttr_t filt_task_attributes = {
  .name = FILT_TASK_NAME,
  .cb_mem = &filt_task_control_block,
  .cb_size = sizeof(filt_task_control_block),
  .stack_mem = &filt_task_buffer[0],
  .stack_size = sizeof(filt_task_buffer),
  .priority = (osPriority_t) osPriorityHigh5,
};
/* Definitions for hil_task */
osThreadId_t hil_taskHandle;
uint32_t hil_task_buffer[ 1024 ];
osStaticThreadDef_t hil_task_control_block;
const osThreadAttr_t hil_task_attributes = {
  .name = "HIL",
  .cb_mem = &hil_task_control_block,
  .cb_size = sizeof(hil_task_control_block),
  .stack_mem = &hil_task_buffer[0],
  .stack_size = sizeof(hil_task_buffer),
  .priority = (osPriority_t) osPriorityHigh6,
};
/* Definitions for dau_uart_mutex */
osMutexId_t dau_uart_mutexHandle;
const osMutexAttr_t dau_uart_mutex_attributes = {
  .name = "dau_uart_mutex"
};
/* USER CODE BEGIN PV */
osEventFlagsId_t print_event_handle = NULL;
/* USER CODE END PV */

void SystemClock_Config(void);
void PeriphCommonClock_Config(void);
static void MPU_Config(void);
static void MX_GPIO_Init(void);
static void MX_DMA_Init(void);
static void MX_BDMA_Init(void);
static void MX_ADC1_Init(void);
static void MX_ADC3_Init(void);
static void MX_DAC1_Init(void);
static void MX_DTS_Init(void);
static void MX_I2C1_Init(void);
static void MX_SPI4_Init(void);
static void MX_TIM3_Init(void);
static void MX_TIM6_Init(void);
static void MX_TIM8_Init(void);
static void MX_ADC2_Init(void);
static void MX_TIM17_Init(void);
static void MX_TIM16_Init(void);
static void MX_CORDIC_Init(void);
static void MX_LPUART1_UART_Init(void);
static void MX_OCTOSPI1_Init(void);
static void MX_RTC_Init(void);
static void MX_SPI3_Init(void);
static void MX_FMAC_Init(void);
void startTusbTask(void *argument);
void startMessTask(void *argument);
void startSystemManagementTask(void *argument);
void startCommunicationTask(void *argument);
void startconfigTask(void *argument);
void startDacTask(void *argument);
void startMacTask(void *argument);
void startFiltTask(void *argument);
void startHilTask(void *argument);

/* USER CODE BEGIN PFP */
static void usbHsInit(void);
/* USER CODE END PFP */

/* USER CODE BEGIN 0 */
extern __IO uint32_t uwTick;
extern HAL_TickFreqTypeDef uwTickFreq;
static uint32_t tick_rollover_count = 0;
void HAL_IncTick(void)
{
  if (uwTick == 0xFFFFFFFF) tick_rollover_count++;
  uwTick += (uint32_t)uwTickFreq;
}

uint32_t HAL_TickRolloverCount(void)
{
  return tick_rollover_count;
}

uint64_t HAL_AbsoluteTimestamp(void)
{
  return uwTick | (((uint64_t) HAL_TickRolloverCount()) << 32);
}

static void usbHsInit(void)
{
  GPIO_InitTypeDef GPIO_InitStruct = {0};
  RCC_PeriphCLKInitTypeDef PeriphClkInitStruct = {0};

  PeriphClkInitStruct.PeriphClockSelection = RCC_PERIPHCLK_USB;
  PeriphClkInitStruct.PLL3.PLL3M = 4;
  PeriphClkInitStruct.PLL3.PLL3N = 120;
  PeriphClkInitStruct.PLL3.PLL3P = 2;
  PeriphClkInitStruct.PLL3.PLL3Q = 5;
  PeriphClkInitStruct.PLL3.PLL3R = 2;
  PeriphClkInitStruct.PLL3.PLL3RGE = RCC_PLL3VCIRANGE_1;
  PeriphClkInitStruct.PLL3.PLL3VCOSEL = RCC_PLL3VCOWIDE;
  PeriphClkInitStruct.PLL3.PLL3FRACN = 0;
  PeriphClkInitStruct.UsbClockSelection = RCC_USBCLKSOURCE_PLL3;
  if (HAL_RCCEx_PeriphCLKConfig(&PeriphClkInitStruct) != HAL_OK)
  {
    Error_Handler();
  }

/** Enable USB Voltage detector
*/
  HAL_PWREx_EnableUSBVoltageDetector();

  __HAL_RCC_GPIOC_CLK_ENABLE();
  __HAL_RCC_GPIOA_CLK_ENABLE();
  __HAL_RCC_GPIOB_CLK_ENABLE();
  /**USB_OTG_HS GPIO Configuration
  PC0     ------> USB_OTG_HS_ULPI_STP
  PC2_C     ------> USB_OTG_HS_ULPI_DIR
  PC3_C     ------> USB_OTG_HS_ULPI_NXT
  PA3     ------> USB_OTG_HS_ULPI_D0
  PA5     ------> USB_OTG_HS_ULPI_CK
  PB0     ------> USB_OTG_HS_ULPI_D1
  PB1     ------> USB_OTG_HS_ULPI_D2
  PB10     ------> USB_OTG_HS_ULPI_D3
  PB11     ------> USB_OTG_HS_ULPI_D4
  PB12     ------> USB_OTG_HS_ULPI_D5
  PB13     ------> USB_OTG_HS_ULPI_D6
  PB5     ------> USB_OTG_HS_ULPI_D7
  */
  GPIO_InitStruct.Pin = GPIO_PIN_0|GPIO_PIN_2|GPIO_PIN_3;
  GPIO_InitStruct.Mode = GPIO_MODE_AF_PP;
  GPIO_InitStruct.Pull = GPIO_NOPULL;
  GPIO_InitStruct.Speed = GPIO_SPEED_FREQ_HIGH;
  GPIO_InitStruct.Alternate = GPIO_AF10_OTG1_HS;
  HAL_GPIO_Init(GPIOC, &GPIO_InitStruct);

  GPIO_InitStruct.Pin = GPIO_PIN_3|GPIO_PIN_5;
  GPIO_InitStruct.Mode = GPIO_MODE_AF_PP;
  GPIO_InitStruct.Pull = GPIO_NOPULL;
  GPIO_InitStruct.Speed = GPIO_SPEED_FREQ_HIGH;
  GPIO_InitStruct.Alternate = GPIO_AF10_OTG1_HS;
  HAL_GPIO_Init(GPIOA, &GPIO_InitStruct);

  GPIO_InitStruct.Pin = GPIO_PIN_0|GPIO_PIN_1|GPIO_PIN_10|GPIO_PIN_11
                        |GPIO_PIN_12|GPIO_PIN_13|GPIO_PIN_5;
  GPIO_InitStruct.Mode = GPIO_MODE_AF_PP;
  GPIO_InitStruct.Pull = GPIO_NOPULL;
  GPIO_InitStruct.Speed = GPIO_SPEED_FREQ_HIGH;
  GPIO_InitStruct.Alternate = GPIO_AF10_OTG1_HS;
  HAL_GPIO_Init(GPIOB, &GPIO_InitStruct);

  /* Peripheral clock enable */
  __HAL_RCC_USB_OTG_HS_CLK_ENABLE();
  __HAL_RCC_USB_OTG_HS_ULPI_CLK_ENABLE();
  /* USB_OTG_HS interrupt Init */
  HAL_NVIC_SetPriority(OTG_HS_EP1_OUT_IRQn, 5, 0);
  HAL_NVIC_EnableIRQ(OTG_HS_EP1_OUT_IRQn);
  HAL_NVIC_SetPriority(OTG_HS_EP1_IN_IRQn, 5, 0);
  HAL_NVIC_EnableIRQ(OTG_HS_EP1_IN_IRQn);
  HAL_NVIC_SetPriority(OTG_HS_IRQn, 5, 0);
  HAL_NVIC_EnableIRQ(OTG_HS_IRQn);
}

/* USER CODE END 0 */

int main(void)
{

  /* MPU Configuration--------------------------------------------------------*/
  MPU_Config();

  /* Enable the CPU Cache */

  /* Enable I-Cache---------------------------------------------------------*/
  SCB_EnableICache();

  /* Enable D-Cache---------------------------------------------------------*/
  SCB_EnableDCache();

  /* MCU Configuration--------------------------------------------------------*/

  /* Reset of all peripherals, Initializes the Flash interface and the Systick. */
  HAL_Init();

  /* Configure the system clock */
  SystemClock_Config();

  /* Configure the peripherals common clocks */
  PeriphCommonClock_Config();

  /* USER CODE BEGIN SysInit */
  CoreDebug->DEMCR |= CoreDebug_DEMCR_TRCENA_Msk; /* Enable trace */
  DWT->CYCCNT = 0;                                /* Reset counter */
  DWT->CTRL |= DWT_CTRL_CYCCNTENA_Msk;            /* Enable CYCCNT */
  /* USER CODE END SysInit */

  /* Initialize all configured peripherals */
  MX_GPIO_Init();
  MX_DMA_Init();
  MX_BDMA_Init();
  MX_ADC1_Init();
  MX_ADC3_Init();
  MX_DAC1_Init();
  MX_DTS_Init();
  MX_I2C1_Init();
  MX_SPI4_Init();
  MX_TIM3_Init();
  MX_TIM6_Init();
  MX_TIM8_Init();
  MX_ADC2_Init();
  MX_TIM17_Init();
  MX_TIM16_Init();
  MX_CORDIC_Init();
  MX_LPUART1_UART_Init();
  MX_OCTOSPI1_Init();
  MX_RTC_Init();
  MX_SPI3_Init();
  MX_FMAC_Init();
  /* USER CODE BEGIN 2 */
  usbHsInit();
  PWRLED_Update(0x0F);
  PWR_Analog(true);
  HAL_Delay(20);
  Ws2812b_Init();

  if (CFG_CreateFlags() == false) {
    Error_Handler();
  }

  if (Param_Init() == false) {
    Error_Handler();
  }

  /* USER CODE END 2 */

  /* Init scheduler */
  osKernelInitialize();
  /* Create the mutex(es) */
  /* creation of dau_uart_mutex */
  dau_uart_mutexHandle = osMutexNew(&dau_uart_mutex_attributes);

  /* USER CODE BEGIN RTOS_QUEUES */
  /* add queues, ... */
  MESS_InitializeQueues();
  /* USER CODE END RTOS_QUEUES */

  /* Create the thread(s) */
  /* creation of tusb_task */
  tusb_taskHandle = osThreadNew(startTusbTask, NULL, &tusb_task_attributes);

  /* creation of message_task */
  message_taskHandle = osThreadNew(startMessTask, NULL, &message_task_attributes);

  /* creation of sys_task */
  sys_taskHandle = osThreadNew(startSystemManagementTask, NULL, &sys_task_attributes);

  /* creation of comm_task */
  comm_taskHandle = osThreadNew(startCommunicationTask, NULL, &comm_task_attributes);

  /* creation of cfg_task */
  cfg_taskHandle = osThreadNew(startconfigTask, NULL, &cfg_task_attributes);

  /* creation of dac_task */
  dac_taskHandle = osThreadNew(startDacTask, NULL, &dac_task_attributes);

  /* creation of mac_task */
  mac_taskHandle = osThreadNew(startMacTask, NULL, &mac_task_attributes);

  /* creation of filt_task */
  filt_taskHandle = osThreadNew(startFiltTask, NULL, &filt_task_attributes);

  /* creation of hil_task */
  hil_taskHandle = osThreadNew(startHilTask, NULL, &hil_task_attributes);

  /* USER CODE BEGIN RTOS_EVENTS */
  /* add events, ... */
  print_event_handle = osEventFlagsNew(NULL);
  /* USER CODE END RTOS_EVENTS */

  /* Start scheduler */
  osKernelStart();

  /* We should never get here as control is now taken by the scheduler */

  /* Infinite loop */
  while (1)
  {

  }
}

void SystemClock_Config(void)
{
  RCC_OscInitTypeDef RCC_OscInitStruct = {0};
  RCC_ClkInitTypeDef RCC_ClkInitStruct = {0};

  /** Supply configuration update enable
  */
  HAL_PWREx_ConfigSupply(PWR_LDO_SUPPLY);

  /** Configure the main internal regulator output voltage
  */
  __HAL_PWR_VOLTAGESCALING_CONFIG(PWR_REGULATOR_VOLTAGE_SCALE0);

  while(!__HAL_PWR_GET_FLAG(PWR_FLAG_VOSRDY)) {}

  /** Initializes the RCC Oscillators according to the specified parameters
  * in the RCC_OscInitTypeDef structure.
  */
  RCC_OscInitStruct.OscillatorType = RCC_OSCILLATORTYPE_HSE|RCC_OSCILLATORTYPE_LSE;
  RCC_OscInitStruct.HSEState = RCC_HSE_ON;
  RCC_OscInitStruct.LSEState = RCC_LSE_BYPASS;
  RCC_OscInitStruct.PLL.PLLState = RCC_PLL_ON;
  RCC_OscInitStruct.PLL.PLLSource = RCC_PLLSOURCE_HSE;
  RCC_OscInitStruct.PLL.PLLM = 1;
  RCC_OscInitStruct.PLL.PLLN = 60;
  RCC_OscInitStruct.PLL.PLLP = 1;
  RCC_OscInitStruct.PLL.PLLQ = 10;
  RCC_OscInitStruct.PLL.PLLR = 2;
  RCC_OscInitStruct.PLL.PLLRGE = RCC_PLL1VCIRANGE_3;
  RCC_OscInitStruct.PLL.PLLVCOSEL = RCC_PLL1VCOWIDE;
  RCC_OscInitStruct.PLL.PLLFRACN = 0;
  if (HAL_RCC_OscConfig(&RCC_OscInitStruct) != HAL_OK)
  {
    Error_Handler();
  }

  /** Initializes the CPU, AHB and APB buses clocks
  */
  RCC_ClkInitStruct.ClockType = RCC_CLOCKTYPE_HCLK|RCC_CLOCKTYPE_SYSCLK
                              |RCC_CLOCKTYPE_PCLK1|RCC_CLOCKTYPE_PCLK2
                              |RCC_CLOCKTYPE_D3PCLK1|RCC_CLOCKTYPE_D1PCLK1;
  RCC_ClkInitStruct.SYSCLKSource = RCC_SYSCLKSOURCE_PLLCLK;
  RCC_ClkInitStruct.SYSCLKDivider = RCC_SYSCLK_DIV1;
  RCC_ClkInitStruct.AHBCLKDivider = RCC_HCLK_DIV2;
  RCC_ClkInitStruct.APB3CLKDivider = RCC_APB3_DIV2;
  RCC_ClkInitStruct.APB1CLKDivider = RCC_APB1_DIV2;
  RCC_ClkInitStruct.APB2CLKDivider = RCC_APB2_DIV2;
  RCC_ClkInitStruct.APB4CLKDivider = RCC_APB4_DIV2;

  if (HAL_RCC_ClockConfig(&RCC_ClkInitStruct, FLASH_LATENCY_3) != HAL_OK)
  {
    Error_Handler();
  }
}

void PeriphCommonClock_Config(void)
{
  RCC_PeriphCLKInitTypeDef PeriphClkInitStruct = {0};

  /** Initializes the peripherals clock
  */
  PeriphClkInitStruct.PeriphClockSelection = RCC_PERIPHCLK_ADC|RCC_PERIPHCLK_SPI4;
  PeriphClkInitStruct.PLL2.PLL2M = 1;
  PeriphClkInitStruct.PLL2.PLL2N = 24;
  PeriphClkInitStruct.PLL2.PLL2P = 4;
  PeriphClkInitStruct.PLL2.PLL2Q = 2;
  PeriphClkInitStruct.PLL2.PLL2R = 2;
  PeriphClkInitStruct.PLL2.PLL2RGE = RCC_PLL2VCIRANGE_3;
  PeriphClkInitStruct.PLL2.PLL2VCOSEL = RCC_PLL2VCOWIDE;
  PeriphClkInitStruct.PLL2.PLL2FRACN = 0;
  PeriphClkInitStruct.Spi45ClockSelection = RCC_SPI45CLKSOURCE_PLL2;
  PeriphClkInitStruct.AdcClockSelection = RCC_ADCCLKSOURCE_PLL2;
  if (HAL_RCCEx_PeriphCLKConfig(&PeriphClkInitStruct) != HAL_OK)
  {
    Error_Handler();
  }
}

static void MX_ADC1_Init(void)
{

  ADC_MultiModeTypeDef multimode = {0};
  ADC_ChannelConfTypeDef sConfig = {0};

  /** Common config
  */
  hadc1.Instance = ADC1;
  hadc1.Init.ClockPrescaler = ADC_CLOCK_ASYNC_DIV1;
  hadc1.Init.Resolution = ADC_RESOLUTION_16B;
  hadc1.Init.ScanConvMode = ADC_SCAN_DISABLE;
  hadc1.Init.EOCSelection = ADC_EOC_SINGLE_CONV;
  hadc1.Init.LowPowerAutoWait = DISABLE;
  hadc1.Init.ContinuousConvMode = DISABLE;
  hadc1.Init.NbrOfConversion = 1;
  hadc1.Init.DiscontinuousConvMode = DISABLE;
  hadc1.Init.ExternalTrigConv = ADC_EXTERNALTRIG_T6_TRGO;
  hadc1.Init.ExternalTrigConvEdge = ADC_EXTERNALTRIGCONVEDGE_RISING;
  hadc1.Init.ConversionDataManagement = ADC_CONVERSIONDATA_DMA_CIRCULAR;
  hadc1.Init.Overrun = ADC_OVR_DATA_PRESERVED;
  hadc1.Init.LeftBitShift = ADC_LEFTBITSHIFT_NONE;
  hadc1.Init.OversamplingMode = DISABLE;
  hadc1.Init.Oversampling.Ratio = 1;
  if (HAL_ADC_Init(&hadc1) != HAL_OK)
  {
    Error_Handler();
  }

  /** Configure the ADC multi-mode
  */
  multimode.Mode = ADC_MODE_INDEPENDENT;
  if (HAL_ADCEx_MultiModeConfigChannel(&hadc1, &multimode) != HAL_OK)
  {
    Error_Handler();
  }

  /** Configure Regular Channel
  */
  sConfig.Channel = ADC_CHANNEL_4;
  sConfig.Rank = ADC_REGULAR_RANK_1;
  sConfig.SamplingTime = ADC_SAMPLETIME_2CYCLES_5;
  sConfig.SingleDiff = ADC_SINGLE_ENDED;
  sConfig.OffsetNumber = ADC_OFFSET_NONE;
  sConfig.Offset = 0;
  sConfig.OffsetSignedSaturation = DISABLE;
  if (HAL_ADC_ConfigChannel(&hadc1, &sConfig) != HAL_OK)
  {
    Error_Handler();
  }
  /* USER CODE BEGIN ADC1_Init 2 */
  HAL_Delay(1);
  if (HAL_ADCEx_Calibration_Start(&hadc1, ADC_CALIB_OFFSET, ADC_SINGLE_ENDED) != HAL_OK)
  {
    Error_Handler();
  }
  /* USER CODE END ADC1_Init 2 */

}

static void MX_ADC2_Init(void)
{

  ADC_ChannelConfTypeDef sConfig = {0};

  /** Common config
  */
  hadc2.Instance = ADC2;
  hadc2.Init.ClockPrescaler = ADC_CLOCK_ASYNC_DIV1;
  hadc2.Init.Resolution = ADC_RESOLUTION_16B;
  hadc2.Init.ScanConvMode = ADC_SCAN_DISABLE;
  hadc2.Init.EOCSelection = ADC_EOC_SINGLE_CONV;
  hadc2.Init.LowPowerAutoWait = DISABLE;
  hadc2.Init.ContinuousConvMode = DISABLE;
  hadc2.Init.NbrOfConversion = 1;
  hadc2.Init.DiscontinuousConvMode = DISABLE;
  hadc2.Init.ExternalTrigConv = ADC_EXTERNALTRIG_T8_TRGO;
  hadc2.Init.ExternalTrigConvEdge = ADC_EXTERNALTRIGCONVEDGE_RISING;
  hadc2.Init.ConversionDataManagement = ADC_CONVERSIONDATA_DMA_CIRCULAR;
  hadc2.Init.Overrun = ADC_OVR_DATA_PRESERVED;
  hadc2.Init.LeftBitShift = ADC_LEFTBITSHIFT_NONE;
  hadc2.Init.OversamplingMode = DISABLE;
  hadc2.Init.Oversampling.Ratio = 1;
  if (HAL_ADC_Init(&hadc2) != HAL_OK)
  {
    Error_Handler();
  }

  /** Configure Regular Channel
  */
  sConfig.Channel = ADC_CHANNEL_3;
  sConfig.Rank = ADC_REGULAR_RANK_1;
  sConfig.SamplingTime = ADC_SAMPLETIME_2CYCLES_5;
  sConfig.SingleDiff = ADC_SINGLE_ENDED;
  sConfig.OffsetNumber = ADC_OFFSET_NONE;
  sConfig.Offset = 0;
  sConfig.OffsetSignedSaturation = DISABLE;
  if (HAL_ADC_ConfigChannel(&hadc2, &sConfig) != HAL_OK)
  {
    Error_Handler();
  }
  /* USER CODE BEGIN ADC2_Init 2 */
  HAL_Delay(1);
  if (HAL_ADCEx_Calibration_Start(&hadc2, ADC_CALIB_OFFSET, ADC_SINGLE_ENDED) != HAL_OK)
  {
    Error_Handler();
  }
  /* USER CODE END ADC2_Init 2 */

}

static void MX_ADC3_Init(void)
{

  ADC_ChannelConfTypeDef sConfig = {0};

  /** Common config
  */
  hadc3.Instance = ADC3;
  hadc3.Init.ClockPrescaler = ADC_CLOCK_ASYNC_DIV1;
  hadc3.Init.Resolution = ADC_RESOLUTION_12B;
  hadc3.Init.DataAlign = ADC3_DATAALIGN_RIGHT;
  hadc3.Init.ScanConvMode = ADC_SCAN_DISABLE;
  hadc3.Init.EOCSelection = ADC_EOC_SINGLE_CONV;
  hadc3.Init.LowPowerAutoWait = DISABLE;
  hadc3.Init.ContinuousConvMode = DISABLE;
  hadc3.Init.NbrOfConversion = 1;
  hadc3.Init.DiscontinuousConvMode = DISABLE;
  hadc3.Init.ExternalTrigConv = ADC_SOFTWARE_START;
  hadc3.Init.ExternalTrigConvEdge = ADC_EXTERNALTRIGCONVEDGE_NONE;
  hadc3.Init.DMAContinuousRequests = DISABLE;
  hadc3.Init.SamplingMode = ADC_SAMPLING_MODE_NORMAL;
  hadc3.Init.ConversionDataManagement = ADC_CONVERSIONDATA_DR;
  hadc3.Init.Overrun = ADC_OVR_DATA_PRESERVED;
  hadc3.Init.LeftBitShift = ADC_LEFTBITSHIFT_NONE;
  hadc3.Init.OversamplingMode = ENABLE;
  hadc3.Init.Oversampling.Ratio = ADC3_OVERSAMPLING_RATIO_16;
  hadc3.Init.Oversampling.RightBitShift = ADC_RIGHTBITSHIFT_4;
  hadc3.Init.Oversampling.TriggeredMode = ADC_TRIGGEREDMODE_SINGLE_TRIGGER;
  hadc3.Init.Oversampling.OversamplingStopReset = ADC_REGOVERSAMPLING_CONTINUED_MODE;
  if (HAL_ADC_Init(&hadc3) != HAL_OK)
  {
    Error_Handler();
  }

  /** Configure Regular Channel
  */
  sConfig.Channel = ADC_CHANNEL_TEMPSENSOR;
  sConfig.Rank = ADC_REGULAR_RANK_1;
  sConfig.SamplingTime = ADC3_SAMPLETIME_640CYCLES_5;
  sConfig.SingleDiff = ADC_SINGLE_ENDED;
  sConfig.OffsetNumber = ADC_OFFSET_NONE;
  sConfig.Offset = 0;
  sConfig.OffsetSign = ADC3_OFFSET_SIGN_NEGATIVE;
  if (HAL_ADC_ConfigChannel(&hadc3, &sConfig) != HAL_OK)
  {
    Error_Handler();
  }
  /* USER CODE BEGIN ADC3_Init 2 */
  HAL_Delay(1);
  if (HAL_ADCEx_Calibration_Start(&hadc3, ADC_CALIB_OFFSET, ADC_SINGLE_ENDED) != HAL_OK)
  {
    Error_Handler();
  }
  /* USER CODE END ADC3_Init 2 */

}

static void MX_CORDIC_Init(void)
{

  hcordic.Instance = CORDIC;
  if (HAL_CORDIC_Init(&hcordic) != HAL_OK)
  {
    Error_Handler();
  }
  /* USER CODE BEGIN CORDIC_Init 2 */
  LL_CORDIC_Config(CORDIC,
                   LL_CORDIC_FUNCTION_SINE,
                   LL_CORDIC_PRECISION_5CYCLES,
                   LL_CORDIC_SCALE_0,
                   LL_CORDIC_NBWRITE_1,
                   LL_CORDIC_NBREAD_1,
                   LL_CORDIC_INSIZE_32BITS,
                   LL_CORDIC_OUTSIZE_32BITS);
  /* USER CODE END CORDIC_Init 2 */

}

static void MX_DAC1_Init(void)
{

  DAC_ChannelConfTypeDef sConfig = {0};

  /** DAC Initialization
  */
  hdac1.Instance = DAC1;
  if (HAL_DAC_Init(&hdac1) != HAL_OK)
  {
    Error_Handler();
  }

  /** DAC channel OUT1 config
  */
  sConfig.DAC_SampleAndHold = DAC_SAMPLEANDHOLD_DISABLE;
  sConfig.DAC_Trigger = DAC_TRIGGER_T6_TRGO;
  sConfig.DAC_OutputBuffer = DAC_OUTPUTBUFFER_ENABLE;
  sConfig.DAC_ConnectOnChipPeripheral = DAC_CHIPCONNECT_DISABLE;
  sConfig.DAC_UserTrimming = DAC_TRIMMING_FACTORY;
  if (HAL_DAC_ConfigChannel(&hdac1, &sConfig, DAC_CHANNEL_1) != HAL_OK)
  {
    Error_Handler();
  }
  /* USER CODE BEGIN DAC1_Init 2 */
  HAL_DACEx_SelfCalibrate(&hdac1, &sConfig, DAC_CHANNEL_1);
  HAL_Delay(1);
  /* USER CODE END DAC1_Init 2 */

}

static void MX_DTS_Init(void)
{

  hdts.Instance = DTS;
  hdts.Init.QuickMeasure = DTS_QUICKMEAS_DISABLE;
  hdts.Init.RefClock = DTS_REFCLKSEL_PCLK;
  hdts.Init.TriggerInput = DTS_TRIGGER_HW_NONE;
  hdts.Init.SamplingTime = DTS_SMP_TIME_1_CYCLE;
  hdts.Init.Divider = 1;
  hdts.Init.HighThreshold = 0x0;
  hdts.Init.LowThreshold = 0x0;
  if (HAL_DTS_Init(&hdts) != HAL_OK)
  {
    Error_Handler();
  }

}

static void MX_FMAC_Init(void)
{

  hfmac.Instance = FMAC;
  if (HAL_FMAC_Init(&hfmac) != HAL_OK)
  {
    Error_Handler();
  }

}

static void MX_I2C1_Init(void)
{

  hi2c1.Instance = I2C1;
  hi2c1.Init.Timing = 0x00B03FDB;
  hi2c1.Init.OwnAddress1 = 0;
  hi2c1.Init.AddressingMode = I2C_ADDRESSINGMODE_7BIT;
  hi2c1.Init.DualAddressMode = I2C_DUALADDRESS_DISABLE;
  hi2c1.Init.OwnAddress2 = 0;
  hi2c1.Init.OwnAddress2Masks = I2C_OA2_NOMASK;
  hi2c1.Init.GeneralCallMode = I2C_GENERALCALL_DISABLE;
  hi2c1.Init.NoStretchMode = I2C_NOSTRETCH_DISABLE;
  if (HAL_I2C_Init(&hi2c1) != HAL_OK)
  {
    Error_Handler();
  }

  /** Configure Analogue filter
  */
  if (HAL_I2CEx_ConfigAnalogFilter(&hi2c1, I2C_ANALOGFILTER_ENABLE) != HAL_OK)
  {
    Error_Handler();
  }

  /** Configure Digital filter
  */
  if (HAL_I2CEx_ConfigDigitalFilter(&hi2c1, 0) != HAL_OK)
  {
    Error_Handler();
  }

}

static void MX_LPUART1_UART_Init(void)
{

  hlpuart1.Instance = LPUART1;
  hlpuart1.Init.BaudRate = 115200;
  hlpuart1.Init.WordLength = UART_WORDLENGTH_8B;
  hlpuart1.Init.StopBits = UART_STOPBITS_1;
  hlpuart1.Init.Parity = UART_PARITY_NONE;
  hlpuart1.Init.Mode = UART_MODE_TX_RX;
  hlpuart1.Init.HwFlowCtl = UART_HWCONTROL_NONE;
  hlpuart1.Init.OneBitSampling = UART_ONE_BIT_SAMPLE_DISABLE;
  hlpuart1.Init.ClockPrescaler = UART_PRESCALER_DIV1;
  hlpuart1.AdvancedInit.AdvFeatureInit = UART_ADVFEATURE_NO_INIT;
  hlpuart1.FifoMode = UART_FIFOMODE_DISABLE;
  if (HAL_UART_Init(&hlpuart1) != HAL_OK)
  {
    Error_Handler();
  }
  if (HAL_UARTEx_SetTxFifoThreshold(&hlpuart1, UART_TXFIFO_THRESHOLD_1_8) != HAL_OK)
  {
    Error_Handler();
  }
  if (HAL_UARTEx_SetRxFifoThreshold(&hlpuart1, UART_RXFIFO_THRESHOLD_1_8) != HAL_OK)
  {
    Error_Handler();
  }
  if (HAL_UARTEx_DisableFifoMode(&hlpuart1) != HAL_OK)
  {
    Error_Handler();
  }

}

static void MX_OCTOSPI1_Init(void)
{

  OSPIM_CfgTypeDef sOspiManagerCfg = {0};

  /* OCTOSPI1 parameter configuration*/
  hospi1.Instance = OCTOSPI1;
  hospi1.Init.FifoThreshold = 1;
  hospi1.Init.DualQuad = HAL_OSPI_DUALQUAD_DISABLE;
  hospi1.Init.MemoryType = HAL_OSPI_MEMTYPE_MICRON;
  hospi1.Init.DeviceSize = 32;
  hospi1.Init.ChipSelectHighTime = 1;
  hospi1.Init.FreeRunningClock = HAL_OSPI_FREERUNCLK_DISABLE;
  hospi1.Init.ClockMode = HAL_OSPI_CLOCK_MODE_0;
  hospi1.Init.WrapSize = HAL_OSPI_WRAP_NOT_SUPPORTED;
  hospi1.Init.ClockPrescaler = 2;
  hospi1.Init.SampleShifting = HAL_OSPI_SAMPLE_SHIFTING_NONE;
  hospi1.Init.DelayHoldQuarterCycle = HAL_OSPI_DHQC_DISABLE;
  hospi1.Init.ChipSelectBoundary = 0;
  hospi1.Init.DelayBlockBypass = HAL_OSPI_DELAY_BLOCK_BYPASSED;
  hospi1.Init.MaxTran = 0;
  hospi1.Init.Refresh = 0;
  if (HAL_OSPI_Init(&hospi1) != HAL_OK)
  {
    Error_Handler();
  }
  sOspiManagerCfg.ClkPort = 1;
  sOspiManagerCfg.NCSPort = 1;
  sOspiManagerCfg.IOLowPort = HAL_OSPIM_IOPORT_1_HIGH;
  if (HAL_OSPIM_Config(&hospi1, &sOspiManagerCfg, HAL_OSPI_TIMEOUT_DEFAULT_VALUE) != HAL_OK)
  {
    Error_Handler();
  }

}

static void MX_RTC_Init(void)
{

  /** Initialize RTC Only
  */
  hrtc.Instance = RTC;
  hrtc.Init.HourFormat = RTC_HOURFORMAT_24;
  hrtc.Init.AsynchPrediv = 127;
  hrtc.Init.SynchPrediv = 255;
  hrtc.Init.OutPut = RTC_OUTPUT_DISABLE;
  hrtc.Init.OutPutPolarity = RTC_OUTPUT_POLARITY_HIGH;
  hrtc.Init.OutPutType = RTC_OUTPUT_TYPE_OPENDRAIN;
  hrtc.Init.OutPutRemap = RTC_OUTPUT_REMAP_NONE;
  if (HAL_RTC_Init(&hrtc) != HAL_OK)
  {
    Error_Handler();
  }

}

static void MX_SPI3_Init(void)
{

  /* SPI3 parameter configuration*/
  hspi3.Instance = SPI3;
  hspi3.Init.Mode = SPI_MODE_MASTER;
  hspi3.Init.Direction = SPI_DIRECTION_2LINES;
  hspi3.Init.DataSize = SPI_DATASIZE_8BIT;
  hspi3.Init.CLKPolarity = SPI_POLARITY_LOW;
  hspi3.Init.CLKPhase = SPI_PHASE_1EDGE;
  hspi3.Init.NSS = SPI_NSS_HARD_OUTPUT;
  hspi3.Init.BaudRatePrescaler = SPI_BAUDRATEPRESCALER_16;
  hspi3.Init.FirstBit = SPI_FIRSTBIT_MSB;
  hspi3.Init.TIMode = SPI_TIMODE_DISABLE;
  hspi3.Init.CRCCalculation = SPI_CRCCALCULATION_DISABLE;
  hspi3.Init.CRCPolynomial = 0x0;
  hspi3.Init.NSSPMode = SPI_NSS_PULSE_ENABLE;
  hspi3.Init.NSSPolarity = SPI_NSS_POLARITY_LOW;
  hspi3.Init.FifoThreshold = SPI_FIFO_THRESHOLD_01DATA;
  hspi3.Init.TxCRCInitializationPattern = SPI_CRC_INITIALIZATION_ALL_ZERO_PATTERN;
  hspi3.Init.RxCRCInitializationPattern = SPI_CRC_INITIALIZATION_ALL_ZERO_PATTERN;
  hspi3.Init.MasterSSIdleness = SPI_MASTER_SS_IDLENESS_00CYCLE;
  hspi3.Init.MasterInterDataIdleness = SPI_MASTER_INTERDATA_IDLENESS_00CYCLE;
  hspi3.Init.MasterReceiverAutoSusp = SPI_MASTER_RX_AUTOSUSP_DISABLE;
  hspi3.Init.MasterKeepIOState = SPI_MASTER_KEEP_IO_STATE_DISABLE;
  hspi3.Init.IOSwap = SPI_IO_SWAP_DISABLE;
  if (HAL_SPI_Init(&hspi3) != HAL_OK)
  {
    Error_Handler();
  }

}

static void MX_SPI4_Init(void)
{

  /* SPI4 parameter configuration*/
  hspi4.Instance = SPI4;
  hspi4.Init.Mode = SPI_MODE_MASTER;
  hspi4.Init.Direction = SPI_DIRECTION_1LINE;
  hspi4.Init.DataSize = SPI_DATASIZE_16BIT;
  hspi4.Init.CLKPolarity = SPI_POLARITY_LOW;
  hspi4.Init.CLKPhase = SPI_PHASE_1EDGE;
  hspi4.Init.NSS = SPI_NSS_HARD_OUTPUT;
  hspi4.Init.BaudRatePrescaler = SPI_BAUDRATEPRESCALER_16;
  hspi4.Init.FirstBit = SPI_FIRSTBIT_MSB;
  hspi4.Init.TIMode = SPI_TIMODE_DISABLE;
  hspi4.Init.CRCCalculation = SPI_CRCCALCULATION_DISABLE;
  hspi4.Init.CRCPolynomial = 0x0;
  hspi4.Init.NSSPMode = SPI_NSS_PULSE_ENABLE;
  hspi4.Init.NSSPolarity = SPI_NSS_POLARITY_LOW;
  hspi4.Init.FifoThreshold = SPI_FIFO_THRESHOLD_01DATA;
  hspi4.Init.TxCRCInitializationPattern = SPI_CRC_INITIALIZATION_ALL_ZERO_PATTERN;
  hspi4.Init.RxCRCInitializationPattern = SPI_CRC_INITIALIZATION_ALL_ZERO_PATTERN;
  hspi4.Init.MasterSSIdleness = SPI_MASTER_SS_IDLENESS_00CYCLE;
  hspi4.Init.MasterInterDataIdleness = SPI_MASTER_INTERDATA_IDLENESS_00CYCLE;
  hspi4.Init.MasterReceiverAutoSusp = SPI_MASTER_RX_AUTOSUSP_DISABLE;
  hspi4.Init.MasterKeepIOState = SPI_MASTER_KEEP_IO_STATE_DISABLE;
  hspi4.Init.IOSwap = SPI_IO_SWAP_DISABLE;
  if (HAL_SPI_Init(&hspi4) != HAL_OK)
  {
    Error_Handler();
  }

}

static void MX_TIM3_Init(void)
{

  TIM_ClockConfigTypeDef sClockSourceConfig = {0};
  TIM_MasterConfigTypeDef sMasterConfig = {0};
  TIM_OC_InitTypeDef sConfigOC = {0};

  htim3.Instance = TIM3;
  htim3.Init.Prescaler = 3-1;
  htim3.Init.CounterMode = TIM_COUNTERMODE_UP;
  htim3.Init.Period = 100-1;
  htim3.Init.ClockDivision = TIM_CLOCKDIVISION_DIV1;
  htim3.Init.AutoReloadPreload = TIM_AUTORELOAD_PRELOAD_DISABLE;
  if (HAL_TIM_Base_Init(&htim3) != HAL_OK)
  {
    Error_Handler();
  }
  sClockSourceConfig.ClockSource = TIM_CLOCKSOURCE_INTERNAL;
  if (HAL_TIM_ConfigClockSource(&htim3, &sClockSourceConfig) != HAL_OK)
  {
    Error_Handler();
  }
  if (HAL_TIM_PWM_Init(&htim3) != HAL_OK)
  {
    Error_Handler();
  }
  sMasterConfig.MasterOutputTrigger = TIM_TRGO_RESET;
  sMasterConfig.MasterSlaveMode = TIM_MASTERSLAVEMODE_DISABLE;
  if (HAL_TIMEx_MasterConfigSynchronization(&htim3, &sMasterConfig) != HAL_OK)
  {
    Error_Handler();
  }
  sConfigOC.OCMode = TIM_OCMODE_PWM1;
  sConfigOC.Pulse = 0;
  sConfigOC.OCPolarity = TIM_OCPOLARITY_LOW;
  sConfigOC.OCFastMode = TIM_OCFAST_DISABLE;
  if (HAL_TIM_PWM_ConfigChannel(&htim3, &sConfigOC, TIM_CHANNEL_1) != HAL_OK)
  {
    Error_Handler();
  }
  HAL_TIM_MspPostInit(&htim3);

}

static void MX_TIM6_Init(void)
{

  TIM_MasterConfigTypeDef sMasterConfig = {0};

  htim6.Instance = TIM6;
  htim6.Init.Prescaler = 120-1;
  htim6.Init.CounterMode = TIM_COUNTERMODE_UP;
  htim6.Init.Period = 4-1;
  htim6.Init.AutoReloadPreload = TIM_AUTORELOAD_PRELOAD_DISABLE;
  if (HAL_TIM_Base_Init(&htim6) != HAL_OK)
  {
    Error_Handler();
  }
  sMasterConfig.MasterOutputTrigger = TIM_TRGO_UPDATE;
  sMasterConfig.MasterSlaveMode = TIM_MASTERSLAVEMODE_DISABLE;
  if (HAL_TIMEx_MasterConfigSynchronization(&htim6, &sMasterConfig) != HAL_OK)
  {
    Error_Handler();
  }

}

static void MX_TIM8_Init(void)
{

  TIM_ClockConfigTypeDef sClockSourceConfig = {0};
  TIM_MasterConfigTypeDef sMasterConfig = {0};

  htim8.Instance = TIM8;
  htim8.Init.Prescaler = 1000-1;
  htim8.Init.CounterMode = TIM_COUNTERMODE_UP;
  htim8.Init.Period = 2-1;
  htim8.Init.ClockDivision = TIM_CLOCKDIVISION_DIV1;
  htim8.Init.RepetitionCounter = 0;
  htim8.Init.AutoReloadPreload = TIM_AUTORELOAD_PRELOAD_ENABLE;
  if (HAL_TIM_Base_Init(&htim8) != HAL_OK)
  {
    Error_Handler();
  }
  sClockSourceConfig.ClockSource = TIM_CLOCKSOURCE_INTERNAL;
  if (HAL_TIM_ConfigClockSource(&htim8, &sClockSourceConfig) != HAL_OK)
  {
    Error_Handler();
  }
  sMasterConfig.MasterOutputTrigger = TIM_TRGO_UPDATE;
  sMasterConfig.MasterOutputTrigger2 = TIM_TRGO2_RESET;
  sMasterConfig.MasterSlaveMode = TIM_MASTERSLAVEMODE_DISABLE;
  if (HAL_TIMEx_MasterConfigSynchronization(&htim8, &sMasterConfig) != HAL_OK)
  {
    Error_Handler();
  }

}

static void MX_TIM16_Init(void)
{

  htim16.Instance = TIM16;
  htim16.Init.Prescaler = 240-1;
  htim16.Init.CounterMode = TIM_COUNTERMODE_UP;
  htim16.Init.Period = 1000-1;
  htim16.Init.ClockDivision = TIM_CLOCKDIVISION_DIV1;
  htim16.Init.RepetitionCounter = 0;
  htim16.Init.AutoReloadPreload = TIM_AUTORELOAD_PRELOAD_DISABLE;
  if (HAL_TIM_Base_Init(&htim16) != HAL_OK)
  {
    Error_Handler();
  }

}

static void MX_TIM17_Init(void)
{

  htim17.Instance = TIM17;
  htim17.Init.Prescaler = 240-1;
  htim17.Init.CounterMode = TIM_COUNTERMODE_UP;
  htim17.Init.Period = 100-1;
  htim17.Init.ClockDivision = TIM_CLOCKDIVISION_DIV1;
  htim17.Init.RepetitionCounter = 0;
  htim17.Init.AutoReloadPreload = TIM_AUTORELOAD_PRELOAD_DISABLE;
  if (HAL_TIM_Base_Init(&htim17) != HAL_OK)
  {
    Error_Handler();
  }

}

static void MX_BDMA_Init(void)
{

  /* DMA controller clock enable */
  __HAL_RCC_BDMA_CLK_ENABLE();

  /* DMA interrupt init */
  /* BDMA_Channel0_IRQn interrupt configuration */
  HAL_NVIC_SetPriority(BDMA_Channel0_IRQn, 5, 0);
  HAL_NVIC_EnableIRQ(BDMA_Channel0_IRQn);
  /* BDMA_Channel1_IRQn interrupt configuration */
  HAL_NVIC_SetPriority(BDMA_Channel1_IRQn, 5, 0);
  HAL_NVIC_EnableIRQ(BDMA_Channel1_IRQn);

}

static void MX_DMA_Init(void)
{

  /* DMA controller clock enable */
  __HAL_RCC_DMA1_CLK_ENABLE();
  __HAL_RCC_DMA2_CLK_ENABLE();

  /* DMA interrupt init */
  /* DMA1_Stream0_IRQn interrupt configuration */
  HAL_NVIC_SetPriority(DMA1_Stream0_IRQn, 5, 0);
  HAL_NVIC_EnableIRQ(DMA1_Stream0_IRQn);
  /* DMA1_Stream1_IRQn interrupt configuration */
  HAL_NVIC_SetPriority(DMA1_Stream1_IRQn, 5, 0);
  HAL_NVIC_EnableIRQ(DMA1_Stream1_IRQn);
  /* DMA1_Stream3_IRQn interrupt configuration */
  HAL_NVIC_SetPriority(DMA1_Stream3_IRQn, 5, 0);
  HAL_NVIC_EnableIRQ(DMA1_Stream3_IRQn);
  /* DMA1_Stream4_IRQn interrupt configuration */
  HAL_NVIC_SetPriority(DMA1_Stream4_IRQn, 5, 0);
  HAL_NVIC_EnableIRQ(DMA1_Stream4_IRQn);
  /* DMA2_Stream0_IRQn interrupt configuration */
  HAL_NVIC_SetPriority(DMA2_Stream0_IRQn, 5, 0);
  HAL_NVIC_EnableIRQ(DMA2_Stream0_IRQn);
  /* DMA2_Stream2_IRQn interrupt configuration */
  HAL_NVIC_SetPriority(DMA2_Stream2_IRQn, 5, 0);
  HAL_NVIC_EnableIRQ(DMA2_Stream2_IRQn);

}

static void MX_GPIO_Init(void)
{
  GPIO_InitTypeDef GPIO_InitStruct = {0};

  /* GPIO Ports Clock Enable */
  __HAL_RCC_GPIOE_CLK_ENABLE();
  __HAL_RCC_GPIOC_CLK_ENABLE();
  __HAL_RCC_GPIOH_CLK_ENABLE();
  __HAL_RCC_GPIOA_CLK_ENABLE();
  __HAL_RCC_GPIOB_CLK_ENABLE();
  __HAL_RCC_GPIOD_CLK_ENABLE();

  /*Configure GPIO pin Output Level */
  HAL_GPIO_WritePin(GPIOE, EN_3V3A_LED_Pin|EN_3V3_LED_Pin|ULPI_RST__Pin|TPA_RESET_Pin
                          |PAMP_FILTER_EN_Pin|EN_30V_LED_Pin|EN_BATT_LED_Pin, GPIO_PIN_RESET);

  /*Configure GPIO pin Output Level */
  HAL_GPIO_WritePin(GPIOC, MAIN_TO_DAU_Pin|EN_30V_Pin|WS_EN_Pin|EN__3V3_Pin, GPIO_PIN_RESET);

  /*Configure GPIO pin Output Level */
  HAL_GPIO_WritePin(DAC_SEL_GPIO_Port, DAC_SEL_Pin, GPIO_PIN_RESET);

  /*Configure GPIO pin Output Level */
  HAL_GPIO_WritePin(GPIOB, OUTPUT_FB_EN__Pin|INPUT_FB_EN_Pin, GPIO_PIN_RESET);

  /*Configure GPIO pin Output Level */
  HAL_GPIO_WritePin(FBK_ATTENUATION_GPIO_Port, FBK_ATTENUATION_Pin, GPIO_PIN_SET);

  /*Configure GPIO pin Output Level */
  HAL_GPIO_WritePin(GPIOD, TR_SEL_Pin|TR_EN_Pin|EN_3V3A_Pin|EN__5V_Pin, GPIO_PIN_RESET);

  /*Configure GPIO pins : EN_3V3A_LED_Pin EN_3V3_LED_Pin ULPI_RST__Pin TPA_RESET_Pin
                           PAMP_FILTER_EN_Pin EN_30V_LED_Pin EN_BATT_LED_Pin */
  GPIO_InitStruct.Pin = EN_3V3A_LED_Pin|EN_3V3_LED_Pin|ULPI_RST__Pin|TPA_RESET_Pin
                          |PAMP_FILTER_EN_Pin|EN_30V_LED_Pin|EN_BATT_LED_Pin;
  GPIO_InitStruct.Mode = GPIO_MODE_OUTPUT_PP;
  GPIO_InitStruct.Pull = GPIO_NOPULL;
  GPIO_InitStruct.Speed = GPIO_SPEED_FREQ_LOW;
  HAL_GPIO_Init(GPIOE, &GPIO_InitStruct);

  /*Configure GPIO pin : PGOOD_5V_Pin */
  GPIO_InitStruct.Pin = PGOOD_5V_Pin;
  GPIO_InitStruct.Mode = GPIO_MODE_INPUT;
  GPIO_InitStruct.Pull = GPIO_NOPULL;
  HAL_GPIO_Init(PGOOD_5V_GPIO_Port, &GPIO_InitStruct);

  /*Configure GPIO pins : MAIN_TO_DAU_Pin EN_30V_Pin WS_EN_Pin EN__3V3_Pin */
  GPIO_InitStruct.Pin = MAIN_TO_DAU_Pin|EN_30V_Pin|WS_EN_Pin|EN__3V3_Pin;
  GPIO_InitStruct.Mode = GPIO_MODE_OUTPUT_PP;
  GPIO_InitStruct.Pull = GPIO_NOPULL;
  GPIO_InitStruct.Speed = GPIO_SPEED_FREQ_LOW;
  HAL_GPIO_Init(GPIOC, &GPIO_InitStruct);

  /*Configure GPIO pins : PGOOD_30V_Pin TPA_FAULT_Pin */
  GPIO_InitStruct.Pin = PGOOD_30V_Pin|TPA_FAULT_Pin;
  GPIO_InitStruct.Mode = GPIO_MODE_INPUT;
  GPIO_InitStruct.Pull = GPIO_NOPULL;
  HAL_GPIO_Init(GPIOA, &GPIO_InitStruct);

  /*Configure GPIO pin : DAC_SEL_Pin */
  GPIO_InitStruct.Pin = DAC_SEL_Pin;
  GPIO_InitStruct.Mode = GPIO_MODE_OUTPUT_PP;
  GPIO_InitStruct.Pull = GPIO_NOPULL;
  GPIO_InitStruct.Speed = GPIO_SPEED_FREQ_LOW;
  HAL_GPIO_Init(DAC_SEL_GPIO_Port, &GPIO_InitStruct);

  /*Configure GPIO pin : TPA_CLIP_OTW_Pin */
  GPIO_InitStruct.Pin = TPA_CLIP_OTW_Pin;
  GPIO_InitStruct.Mode = GPIO_MODE_INPUT;
  GPIO_InitStruct.Pull = GPIO_NOPULL;
  HAL_GPIO_Init(TPA_CLIP_OTW_GPIO_Port, &GPIO_InitStruct);

  /*Configure GPIO pins : OUTPUT_FB_EN__Pin INPUT_FB_EN_Pin */
  GPIO_InitStruct.Pin = OUTPUT_FB_EN__Pin|INPUT_FB_EN_Pin;
  GPIO_InitStruct.Mode = GPIO_MODE_OUTPUT_PP;
  GPIO_InitStruct.Pull = GPIO_NOPULL;
  GPIO_InitStruct.Speed = GPIO_SPEED_FREQ_LOW;
  HAL_GPIO_Init(GPIOB, &GPIO_InitStruct);

  /*Configure GPIO pins : FBK_ATTENUATION_Pin TR_SEL_Pin TR_EN_Pin EN_3V3A_Pin
                           EN__5V_Pin */
  GPIO_InitStruct.Pin = FBK_ATTENUATION_Pin|TR_SEL_Pin|TR_EN_Pin|EN_3V3A_Pin
                          |EN__5V_Pin;
  GPIO_InitStruct.Mode = GPIO_MODE_OUTPUT_PP;
  GPIO_InitStruct.Pull = GPIO_NOPULL;
  GPIO_InitStruct.Speed = GPIO_SPEED_FREQ_LOW;
  HAL_GPIO_Init(GPIOD, &GPIO_InitStruct);

  /*Configure GPIO pin : LPS_INT_DRDY_Pin */
  GPIO_InitStruct.Pin = LPS_INT_DRDY_Pin;
  GPIO_InitStruct.Mode = GPIO_MODE_IT_RISING;
  GPIO_InitStruct.Pull = GPIO_PULLDOWN;
  HAL_GPIO_Init(LPS_INT_DRDY_GPIO_Port, &GPIO_InitStruct);

  /*Configure GPIO pins : HW_ID_PIN0_Pin HW_ID_PIN1_Pin HW_ID_PIN2_Pin HW_ID_PIN3_Pin */
  GPIO_InitStruct.Pin = HW_ID_PIN0_Pin|HW_ID_PIN1_Pin|HW_ID_PIN2_Pin|HW_ID_PIN3_Pin;
  GPIO_InitStruct.Mode = GPIO_MODE_INPUT;
  GPIO_InitStruct.Pull = GPIO_NOPULL;
  HAL_GPIO_Init(GPIOD, &GPIO_InitStruct);

  /* EXTI interrupt init*/
  HAL_NVIC_SetPriority(LPS_INT_DRDY_EXTI_IRQn, 5, 0);
  HAL_NVIC_EnableIRQ(LPS_INT_DRDY_EXTI_IRQn);

  /* USER CODE BEGIN MX_GPIO_Init_2 */
  PWR_Analog(true);
  HAL_GPIO_WritePin(ULPI_RST__GPIO_Port, ULPI_RST__Pin, GPIO_PIN_SET);
  HAL_Delay(100); // Small delay to ensure that voltage rails have stabilized
  /* USER CODE END MX_GPIO_Init_2 */
}

void startTusbTask(void *argument)
{
  /* USER CODE BEGIN 5 */
  USB_StartTask(argument);
  /* USER CODE END 5 */
}

void startMessTask(void *argument)
{
  /* USER CODE BEGIN startMessTask */
  MESS_StartTask(argument);
  /* USER CODE END startMessTask */
}

void startSystemManagementTask(void *argument)
{
  /* USER CODE BEGIN startSystemManagementTask */
  SYS_StartTask(argument);
  /* USER CODE END startSystemManagementTask */
}

void startCommunicationTask(void *argument)
{
  /* USER CODE BEGIN startCommunicationTask */
  COMM_StartTask(argument);
  /* USER CODE END startCommunicationTask */
}

void startconfigTask(void *argument)
{
  /* USER CODE BEGIN startconfigTask */
  CFG_StartTask(argument);
  /* USER CODE END startconfigTask */
}

void startDacTask(void *argument)
{
  /* USER CODE BEGIN startDacTask */
  /* Infinite loop */
  DAC_StartTask(argument);
  /* USER CODE END startDacTask */
}

void startMacTask(void *argument)
{
  /* USER CODE BEGIN startMacTask */
  MAC_StartTask(argument);
  /* USER CODE END startMacTask */
}

void startFiltTask(void *argument)
{
  /* USER CODE BEGIN startFiltTask */
  FILT_StartTask(argument);
  /* USER CODE END startFiltTask */
}

void startHilTask(void *argument)
{
  /* USER CODE BEGIN startHilTask */
  HIL_StartTask(argument);
  /* USER CODE END startHilTask */
}

 /* MPU Configuration */

void MPU_Config(void)
{
  MPU_Region_InitTypeDef MPU_InitStruct = {0};

  /* Disables the MPU */
  HAL_MPU_Disable();

  /** Initializes and configures the Region and the memory to be protected
  */
  MPU_InitStruct.Enable = MPU_REGION_ENABLE;
  MPU_InitStruct.Number = MPU_REGION_NUMBER0;
  MPU_InitStruct.BaseAddress = 0x0;
  MPU_InitStruct.Size = MPU_REGION_SIZE_4GB;
  MPU_InitStruct.SubRegionDisable = 0x87;
  MPU_InitStruct.TypeExtField = MPU_TEX_LEVEL0;
  MPU_InitStruct.AccessPermission = MPU_REGION_NO_ACCESS;
  MPU_InitStruct.DisableExec = MPU_INSTRUCTION_ACCESS_DISABLE;
  MPU_InitStruct.IsShareable = MPU_ACCESS_NOT_SHAREABLE;
  MPU_InitStruct.IsCacheable = MPU_ACCESS_NOT_CACHEABLE;
  MPU_InitStruct.IsBufferable = MPU_ACCESS_NOT_BUFFERABLE;

  HAL_MPU_ConfigRegion(&MPU_InitStruct);

  /** Initializes and configures the Region and the memory to be protected
  */
  MPU_InitStruct.Number = MPU_REGION_NUMBER1;
  MPU_InitStruct.BaseAddress = 0x30000000;
  MPU_InitStruct.Size = MPU_REGION_SIZE_32KB;
  MPU_InitStruct.SubRegionDisable = 0x0;
  MPU_InitStruct.AccessPermission = MPU_REGION_FULL_ACCESS;

  HAL_MPU_ConfigRegion(&MPU_InitStruct);

  /** Initializes and configures the Region and the memory to be protected
  */
  MPU_InitStruct.Number = MPU_REGION_NUMBER2;
  MPU_InitStruct.BaseAddress = 0x38800000;
  MPU_InitStruct.Size = MPU_REGION_SIZE_4KB;

  HAL_MPU_ConfigRegion(&MPU_InitStruct);
  /* Enables the MPU */
  HAL_MPU_Enable(MPU_PRIVILEGED_DEFAULT);

}

void HAL_TIM_PeriodElapsedCallback(TIM_HandleTypeDef *htim)
{
  if (htim->Instance == TIM2)
  {
    HAL_IncTick();
  }
}

void Error_Handler(void)
{
  __disable_irq();
  while (1)
  {
  }
}

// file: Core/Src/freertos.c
/* USER CODE BEGIN Header */
/**
  ******************************************************************************
  * File Name          : freertos.c
  * Description        : Code for freertos applications
  ******************************************************************************
  * @attention
  *
  * Copyright (c) 2025 STMicroelectronics.
  * All rights reserved.
  *
  * This software is licensed under terms that can be found in the LICENSE file
  * in the root directory of this software component.
  * If no LICENSE file comes with this software, it is provided AS-IS.
  *
  ******************************************************************************
  */

  /**
  * Modifications Copyright (c) 2025 OpenAquatix Contributors
  * Licensed under MIT License (see LICENSE file)
  *
  * Modified by: Addition of profiling hook
  */
/* USER CODE END Header */

#include "FreeRTOS.h"
#include "task.h"
#include "main.h"

/* Hook prototypes */
void configureTimerForRunTimeStats(void);
unsigned long getRunTimeCounterValue(void);
void vApplicationStackOverflowHook(xTaskHandle xTask, char *pcTaskName);

/* USER CODE BEGIN 1 */
/* Functions needed when configGENERATE_RUN_TIME_STATS is on */
extern TIM_HandleTypeDef htim17;
__weak void configureTimerForRunTimeStats(void)
{
  HAL_TIM_Base_Start_IT(&htim17);
}

extern volatile unsigned long ulHighFrequencyTimerTicks;
__weak unsigned long getRunTimeCounterValue(void)
{
  return ulHighFrequencyTimerTicks;
}
/* USER CODE END 1 */

/* USER CODE BEGIN 4 */
void vApplicationStackOverflowHook(xTaskHandle xTask, char *pcTaskName)
{
   /* Run time stack overflow checking is performed if
   configCHECK_FOR_STACK_OVERFLOW is defined to 1 or 2. This hook function is
   called if a stack overflow is detected. */
  (void)(xTask);
  (void)(pcTaskName);
}
/* USER CODE END 4 */

/* USER CODE BEGIN PREPOSTSLEEP */
__weak void PreSleepProcessing(uint32_t ulExpectedIdleTime)
{
  (void)(ulExpectedIdleTime);
/* place for user code */
}

__weak void PostSleepProcessing(uint32_t ulExpectedIdleTime)
{
  (void)(ulExpectedIdleTime);
/* place for user code */
}
/* USER CODE END PREPOSTSLEEP */
